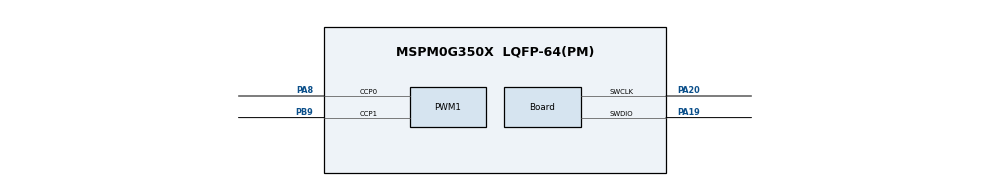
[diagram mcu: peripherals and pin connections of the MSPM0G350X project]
// @cliArgs --device "MSPM0G350X" --package "LQFP-64(PM)" --part "Default"
// @cliArgs --board /ti/boards/LP_MSPM0G3507 --rtos nortos

/**
 * Import the modules used in this configuration.
 */
const PWM  = scripting.addModule("/ti/driverlib/PWM", {}, false);
const PWM1 = PWM.addInstance();

/**
 * Write custom configuration values to the imported modules.
 */
PWM1.$name                           = "PWM_0";
PWM1.clockPrescale                   = 256;
PWM1.timerCount                      = 2000;
PWM1.deadBandEn                      = true;
PWM1.dbRiseDelayTimerCount           = 50;
PWM1.dbFallDelayTimerCount           = 25;
PWM1.ccIndexCmpl                     = [0,1];
PWM1.peripheral.$assign              = "TIMA0";
PWM1.peripheral.ccp0Pin.$assign      = "PA8";
PWM1.peripheral.ccp1Pin.$assign      = "PB9";
PWM1.peripheral.ccp0Pin_cmpl.$assign = "PA22";
PWM1.peripheral.ccp1Pin_cmpl.$assign = "PA25";
PWM1.PWM_CHANNEL_0.$name             = "ti_driverlib_pwm_PWMTimerCC0";
PWM1.PWM_CHANNEL_0.dutyCycle         = 50;
PWM1.PWM_CHANNEL_1.$name             = "ti_driverlib_pwm_PWMTimerCC1";
PWM1.PWM_CHANNEL_1.dutyCycle         = 75;

const Board                       = scripting.addModule("/ti/driverlib/Board", {}, false);
Board.peripheral.$assign          = "DEBUGSS";
Board.peripheral.swclkPin.$assign = "PA20";
Board.peripheral.swdioPin.$assign = "PA19";

const SYSCTL              = scripting.addModule("/ti/driverlib/SYSCTL", {}, false);
SYSCTL.peripheral.$assign = "SYSCTL";

SYSCTL.forceDefaultClkConfig = true;
